# NUC400_v1 register map
File version: 1.0
Registers are 32-bit, read-write, reset 0x0 unless marked. A register's access mark holds for its fields unless they carry their own. Offsets are from the block's base; [hi:lo] are bit positions; {n}, {i} and the like mark numbered series; 'fields as' and 'values as' point back to an identical list.

## PWM0 — PWM Register Map
Base 0x40058000
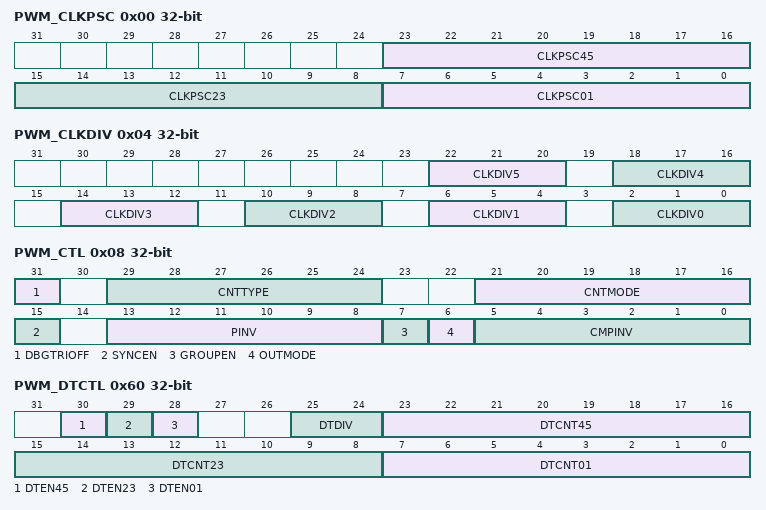
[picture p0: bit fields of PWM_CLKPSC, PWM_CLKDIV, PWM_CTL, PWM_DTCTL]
0x00 PWM_CLKPSC — PWM Clock Prescale Register
  [23:16] CLKPSC45 — PWM Counter Base-Clock Prescale For PWM Pair Of Channel 4 And Channel 5. The base-clock of PWM counter is decided by clock pre-scalar and clock divider. Each PWM pair share one PWM counter base-clock prescaler. The base-clock of PWM counter is divided by (CLKPSC45 + 1). If the value of CLKPSC45 is zero, the base-clock prescaler will stop output clock and corresponding PWM counter will also stop.
  [15:8] CLKPSC23 — PWM Counter Base-Clock Prescale For PWM Pair Of Channel 2 And Channel 3. The base-clock of PWM counter is decided by clock pre-scalar and clock divider. Each PWM pair share one PWM counter base-clock prescaler. The base-clock of PWM counter is divided by (CLKPSC23 + 1). If the value of CLKPSC23 is zero, the base-clock prescaler will stop output clock and corresponding PWM counter will also stop.
  [7:0] CLKPSC01 — PWM Counter Base-Clock Prescale For PWM Pair Of Channel 0 And Channel 1. The base-clock of PWM counter is decided by clock pre-scalar and clock divider. Each PWM pair share one PWM counter base-clock prescaler. The base-clock of PWM counter is divided by (CLKPSC01 + 1). If the value of CLKPSC01 is zero, the base-clock prescaler will stop output clock and corresponding PWM counter will also stop.
0x04 PWM_CLKDIV — PWM Clock Divide Register
  [22:20] CLKDIV5 — PWM Counter Base-Clock Divide For PWMx_CH5. The base-clock of PWM counter is decided by clock pre-scalar and clock divider. Each PWM counter has independent clock divider control register and the divided value is listed in the table below:
    0=2; 1=4; 2=8; 3=16; 4=1
  [4n+2:4n] CLKDIV{n} (n=0..4) — PWM Counter Base-Clock Divide For PWMx_CH{n} (Table is the same as CLKDIV5)
0x08 PWM_CTL — PWM Control Register
  [31] DBGTRIOFF — ICE Debug Mode Acknowledge Disable Bit (Write Protect). Note: The PWM pin will keep output no matter ICE debug mode acknowledged or not.
    0=ICE debug mode acknowledgement effects PWM output; 1=ICE debug mode acknowledgement disabled
  [29:24] CNTTYPE — PWM Counter Operation Aligned Type. Note: Each bit control corresponding PWM channel
    0=PWM counter operating as Edge-aligned type; 1=PWM counter operating as Center-aligned type
  [21:16] CNTMODE — PWM Counter Operation Mode. Note: Each bit control corresponding PWM channel. Note: If there is a transition at this bit, it will cause PWM_PERIODn and PWM_CMPDATn be cleared.
    0=PWM counter working as One-shot mode; 1=PWM counter working as Auto-reload mode
  [15] SYNCEN — Synchronous Mode Enable Bit. Note: If Group and Synchronous mode are enabled simultaneously, the Synchronous mode will be inactive.
    0=The signals timing of each PWM channel are independent; 1=Unify the signals timing of PWM_CH0 and PWM_CH1 in the same phase which is controlled by PWM0 and so as another two PWM pair
  [13:8] PINV — PWM Output Polar Inverse Enable Bit. The register controls polarity state of PWM output. Note: Each bit controls the corresponding PWM channel.
    0=PWM output polar inverse Disabled; 1=PWM output polar inverse Enabled
  [7] GROUPEN — Group Mode Enable Bit
    0=The signals timing of each PWM channel are independent; 1=Unify the signals timing of PWM_CH0, PWM_CH2 and PWM_CH4 in the same phase which is controlled by PWM_CH0 and unify the signals timing of PWM_CH1, PWM_CH3 and PWM_CH5 in the same phase which is controlled by PWM_CH1
  [6] OUTMODE — PWM Output Mode. The register controls the output mode of PWM
    0=PWM output at independent mode; 1=PWM output at complementary mode
  [5:0] CMPINV — PWM Comparator Output Inverter Enable Bit. When CMPINV is set to high, the PWM comparator output signals will be inversed, Note: Each bit control corresponding PWM channel
    0=Comparator output inverter Disabled; 1=Comparator output inverter Enabled
0x0C PWM_CNTEN — PWM Counter Enable Control Register
  [5:0] CNTEN — PWM Counter Enable Bit. Note: Each bit controls the corresponding PWM channel.
    0=PWM Counter Stop Running; 1=PWM Counter Start Running
{0x10+4i} PWM_PERIOD{i} (i=0..5) — PWM Period Register {i}
  [15:0] PERIOD — PWM Period Register. PERIOD determines the PWM period. Note1: Any write to PERIOD will take effect in next PWM cycle. Note2: When PWM operating at center-aligned type, PERIOD value should be set between 0x0000 to 0xFFFE. If PERIOD equal to 0xFFFF, the PWM will work unpredictable. Note3: When PERIOD value is set to 0, PWM output is always high.
{0x28+4i} PWM_CMPDAT{i} (i=0..5) — PWM Comparator Register {i}
  [15:0] CMP — PWM Compare Register. CMP determines the PWM duty. Note: Any write to CMP will take effect in next PWM cycle.
{0x40+4i} PWM_CNT{i} ro (i=0..5) — PWM Data Register {i}
  [15:0] CNT — PWM Data Register. User can monitor CNT to know the current value in 16-bit down counter. Note: It is recommended that read this register when PWM engine clock is source from system clock, otherwise a transition value of PWM counter may be read.
0x58 PWM_MSKEN — PWM Mask Control Register
  [5:0] MSKEN — PWM Mask Enable Bits. The PWM output signal will be masked when this bit is enabled. The corresponding PWMn channel will be output with MSKDAT data. Note: Each bit controls the corresponding PWM channel.
    0=PWM output signal is non-masked; 1=PWM output signal is masked and output with MSKDAT data
0x5C PWM_MSK — PWM Mask Data Register
  [5:0] MSKDAT — PWM Mask Data Bit: This data bit control the state of PWMn output pin, if corresponding mask function is enabled. Note: Each bit controls the corresponding PWM channel.
    0=Output logic low to PWMn; 1=Output logic high to PWMn
0x60 PWM_DTCTL — PWM Dead-zone Control Register
  [30] DTEN45 — Dead-Zone Enable Control for PWM Pair Of Channel 4 and Channel 5. Dead-zone insertion is only active when this pair of complementary PWM is enabled. If Dead-zone insertion is inactive, the outputs of pin pair are complementary without any delay.
    0=Dead-zone insertion Disabled; 1=Dead-zone insertion Enabled
  [29] DTEN23 — Dead-Zone Enable Control for PWM Pair Of Channel 2 and Channel 3. Dead-zone insertion is only active when this pair of complementary PWM is enabled. If Dead-zone insertion is inactive, the outputs of pin pair are complementary without any delay.
    values as DTEN45
  [28] DTEN01 — Dead-Zone Enable Control for PWM Pair Of Channel 0 and Channel 1. Dead-zone insertion is only active when this pair of complementary PWM is enabled. If Dead-zone insertion is inactive, the outputs of pin pair are complementary without any delay.
    values as DTEN45
  [25:24] DTDIV — Dead-Zone Generator Divider
    0=Dead-zone clock equal to PWM base clock divide 1; 1=Dead-zone clock equal to PWM base clock divide 2; 2=Dead-zone clock equal to PWM base clock divide 4; 3=Dead-zone clock equal to PWM base clock divide 8
  [23:16] DTCNT45 — Dead-Zone Interval For PWM Pair Of Channel 4 And Channel 5. These 8-bit determine the Dead-zone length. The unit time of Dead-zone length is received from corresponding PWM_CLKDIV.
  [15:8] DTCNT23 — Dead-Zone Interval For PWM Pair Of Channel 2 And Channel 3. These 8-bit determine the Dead-zone length. The unit time of Dead-zone length is received from corresponding PWM_CLKDIV.
  [7:0] DTCNT01 — Dead-Zone Interval For PWM Pair Of Channel 0 And Channel 1. These 8-bit determine the Dead-zone length. The unit time of Dead-zone length is received from corresponding PWM_CLKDIV.
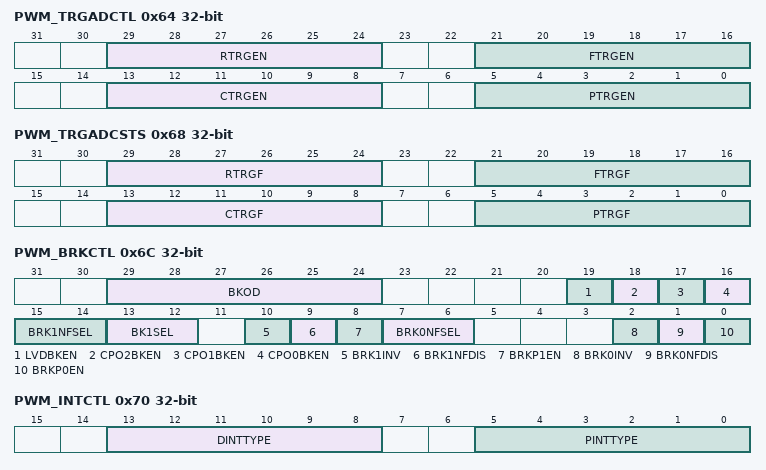
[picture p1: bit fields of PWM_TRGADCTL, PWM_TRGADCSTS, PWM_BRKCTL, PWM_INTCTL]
0x64 PWM_TRGADCTL — PWM Trigger Control Register
  [29:24] RTRGEN — PWM Rising Edge Point Trigger Enable Bits. PWM can trigger ADC to start conversion when PWM output pin rising edge is detected if this bit is set to1. Note: Each bit controls the corresponding PWM channel.
    0=PWM rising edge point trigger ADC function Disabled; 1=PWM rising edge point trigger ADC function Enabled
  [21:16] FTRGEN — PWM Falling Edge Point Trigger Enable Bits. PWM can trigger ADC to start conversion when PWM output pin falling edge is detected if this bit is set to1. Note: Each bit controls the corresponding PWM channel.
    0=PWM falling edge point trigger ADC function Disabled; 1=PWM falling edge point trigger ADC function Enabled
  [13:8] CTRGEN — PWM Center Point Trigger Enable Bits. PWM can trigger ADC to start conversion when PWM counter up count to (PERIODn+1) if this bit is set to1. Note1: This bit should keep at 0 when PWM counter operating in Edge-aligned type. Note2: Each bit controls the corresponding PWM channel.
    0=PWM center point trigger ADC function Disabled; 1=PWM center point trigger ADC function Enabled
  [5:0] PTRGEN — PWM Period Point Trigger Enable Bits. PWM can trigger ADC to start conversion when PWM counter down count to zero if this bit is set to1. Note: Each bit controls the corresponding PWM channel.
    0=PWM period point trigger ADC function Disabled; 1=PWM period point trigger ADC function Enabled
0x68 PWM_TRGADCSTS — PWM Trigger ADC Status Register
  [29:24] RTRGF — PWM Rising Edge Point Trigger Indicator. This bit is set to 1 by hardware when PWM output pin rising edge is detected if corresponding RETRGEN bit is 1. After this bit is set to 1, ADC will start conversion if ADC triggered source is selected by PWM. Note1: Write 1 to clear this bit. Note2: Each bit controls the corresponding PWM channel.
  [21:16] FTRGF — PWM Falling Edge Point Trigger Indicator. This bit is set to 1 by hardware when PWM output pin falling edge is detected if corresponding FETRGEN bit is 1. After this bit is set to 1, ADC will start conversion if ADC triggered source is selected by PWM. Note1: Write 1 to clear this bit. Note2: Each bit controls the corresponding PWM channel.
  [13:8] CTRGF — PWM Center Point Trigger Flag. This bit is set to 1 by hardware when PWM counter up counts to (PERIODn+1) if the corresponding CTRGEN bit is 1. After this bit is set to 1, ADC will start conversion if ADC triggered source is selected by PWM. Note1: Write 1 to clear this bit. Note2: Each bit controls the corresponding PWM channel.
  [5:0] PTRGF — PWM Period Point Trigger Flag. This bit is set to 1 by hardware when PWM counter down count to zero if corresponding PTRGEN bit is 1. After this bit is set to 1, ADC will start conversion if ADC triggered source is selected by PWM. Note1: Write 1 to clear this bit. Note2: Each bit controls the corresponding PWM channel.
0x6C PWM_BRKCTL — PWM Brake Control Register
  [29:24] BKOD — PWM Brake Output Data Register. Note: Each bit controls the corresponding PWM channel.
    0=PWM output low when fault brake conditions asserted; 1=PWM output high when fault brake conditions asserted
  [19] LVDBKEN — Low-Level Detection Trigger PWM Brake Function 1 Enable Bit
    0=Brake Function 1 triggered by Low-level detection Disabled; 1=Brake Function 1 triggered by Low-level detection Enabled
  [18] CPO2BKEN — CPO2 Digital Output As Brake 0 Source Enable Bit
    0=CPO2 as one brake source in Brake 0 Disabled; 1=CPO2 as one brake source in Brake 0 Enabled
  [17] CPO1BKEN — CPO1 Digital Output As Brake 0 Source Enable Bit
    0=CPO1 as one brake source in Brake 0 Disabled; 1=CPO1 as one brake source in Brake 0 Enabled
  [16] CPO0BKEN — CPO0 Digital Output As Brake0 Source Enable Bit
    0=CPO0 as one brake source in Brake 0 Disabled; 1=CPO0 as one brake source in Brake 0 Enabled
  [15:14] BRK1NFSEL — Brake 1 (BKPx1 Pin) Edge Detector Filter Clock Selection
    0=Filter clock = HCLK; 1=Filter clock = HCLK/2; 2=Filter clock = HCLK/4; 3=Filter clock = HCLK/16
  [13:12] BK1SEL — Brake Function 1 Source Selection
    0=From external pin BKP1; 1=From analog comparator 0 output (CPO0); 2=From analog comparator 1 output (CPO1)
  [10] BRK1INV — Inverse BKP1 State
    0=The state of pin BKPx1 is passed to the negative edge detector; 1=The inversed state of pin BKPx1 is passed to the negative edge detector
  [9] BRK1NFDIS — PWM Brake 1 Noise Filter Disable Bit
    0=Noise filter of PWM Brake 1 Enabled; 1=Noise filter of PWM Brake 1 Disabled
  [8] BRKP1EN — Brake1 Function Enable Bit
    0=Brake1 function Disabled; 1=Brake1 function Enabled
  [7:6] BRK0NFSEL — Brake 0 (BKPx0 Pin) Edge Detector Filter Clock Selection
    values as BRK1NFSEL
  [2] BRK0INV — Inverse BKP0 State
    0=The state of pin BKPx0 is passed to the negative edge detector; 1=The inversed state of pin BKPx0 is passed to the negative edge detector
  [1] BRK0NFDIS — PWM Brake 0 Noise Filter Disable Bit
    0=Noise filter of PWM Brake 0 Enabled; 1=Noise filter of PWM Brake 0 Disabled
  [0] BRKP0EN — Brake0 Function Enable Bit
    0=Brake0 detect function Disabled; 1=Brake0 detect function Enabled
0x70 PWM_INTCTL — PWM Interrupt Control Register
  [13:8] DINTTYPE — PWM Duty Interrupt Type Selection. Note1: This bit should keep at 0 when PWM counter operating in Edge-aligned type. Note2: Each bit controls the corresponding PWM channel.
    0=DIF[n] will be set if PWM counter matches PWM_CMPDATn register during down counting; 1=DIF[n] will be set if PWM counter matches PWM_CMPDATn register during up counting
  [5:0] PINTTYPE — PWM Period Interrupt Type Selection. Note1: This bit should keep at 0 when PWM counter operating in Edge-aligned type. Note2: Each bit controls the corresponding PWM channel.
    0=PIF[n] will be set if PWM counter underflow; 1=PIF[n] will be set if PWM counter matches PWM_PERIODn register
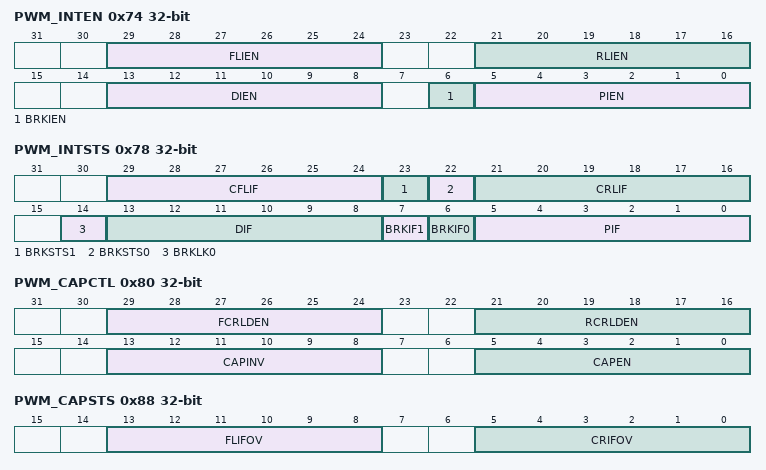
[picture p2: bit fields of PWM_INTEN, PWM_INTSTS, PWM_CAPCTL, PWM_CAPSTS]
0x74 PWM_INTEN — PWM Interrupt Enable Control Register
  [29:24] FLIEN — Falling Latch Interrupt Enable Bit. Note: Each bit controls the corresponding PWM channel.
    0=Falling latch interrupt Disabled; 1=Falling latch interrupt Enabled
  [21:16] RLIEN — Rising Latch Interrupt Enable Bits. Note: Each bit controls the corresponding PWM channel.
    0=Rising latch interrupt Disabled; 1=Rising latch interrupt Enabled
  [13:8] DIEN — PWM Duty Interrupt Enable Bits. Note: Each bit controls the corresponding PWM channel.
    0=Duty interrupt Disabled; 1=Duty interrupt Enabled
  [6] BRKIEN — Brake0 and Brak1 Interrupt Enable Bit
    0=Disabling flags BFK0 and BFK1 to trigger PWM interrupt; 1=Enabling flags BRKIF0 and BRKIF1 can trigger PWM interrupt
  [5:0] PIEN — PWM Period Interrupt Enable Bits. Note: Each bit controls the corresponding PWM channel.
    0=Period interrupt Disabled; 1=Period interrupt Enabled
0x78 PWM_INTSTS — PWM Interrupt Flag Register
  [29:24] CFLIF — Capture Falling Latch Interrupt Flag. Note: This bit must be cleared by writing 1 to it.
    0=No capture falling latch condition happened; 1=Capture falling latch condition happened, this flag will be set to high
  [23] BRKSTS1 ro — Brake 1 Status (Read Only)
    0=PWM had been out of Brake 1 state; 1=PWM is in Brake 1 state
  [22] BRKSTS0 ro — Brake 0 Status (Read Only)
    0=PWM had been out of Brake 0 state; 1=PWM is in Brake 0 state
  [21:16] CRLIF — Capture Rising Latch Interrupt Flag. Note: This bit must be cleared by writing 1 to it.
    0=No capture rising latch condition happened; 1=Capture rising latch condition happened, this flag will be set to high
  [14] BRKLK0 — PWM Brake0 Locked. Note: This bit must be cleared by writing 1 to it.
    0=Brake 0 state is released; 1=When PWM Brake detects a falling signal at BKP0, this flag will be set to high to indicate the Brake0 state is locked
  [13:8] DIF — PWM Duty Interrupt Flag. Flag is set by hardware when channel 0 PWM counter down count and reaches CMP0. Software can clear this bit by writing 1 to it. Note: If CMP is equal to PERIOD, this flag is not working in edge-aligned type selection.
  [7] BRKIF1 — PWM Brake1 Flag. Note: This bit must be cleared by writing 1 to it.
    0=PWM Brake 1 is able to poll falling signal at BKP1 and has not recognized any one; 1=When PWM Brake 1 detects a falling signal at pin BKP1, this flag will be set to high
  [6] BRKIF0 — PWM Brake0 Flag. Note: This bit must be cleared by writing 1 to it.
    0=PWM Brake 0 is able to poll falling signal at BKP0 and has not recognized any one; 1=When PWM Brake 0 detects a falling signal at BKP0, this flag will be set to high
  [5:0] PIF — PWM Period Interrupt Flag. This bit is set by hardware when PWM counter reaches the requirement condition of interrupt (depending on PINTTYPE (PWM_INTCTL[n]) ). Software can write 1 to clear this bit to 0.
0x7C PWM_POEN — PWM Output Enable Control Register
  [5:0] POEN — PWM Pin Output Enable Bit. Note: Each bit controls the corresponding PWM channel.
    0=PWM pin at tri-state; 1=PWM pin in output mode
0x80 PWM_CAPCTL — PWM Capture Control Register
  [29:24] FCRLDEN — Falling Latch Reload Enable Bits
    0=Falling latch reload counter Disabled; 1=Falling latch reload counter Enabled
  [21:16] RCRLDEN — Rising Latch Reload Enable Bits
    0=Rising latch reload counter Enabled; 1=Rising latch reload counter Enabled
  [13:8] CAPINV — Capture Inverter Enable Bits. Note: Each bit controls the corresponding PWM channel.
    0=Capture source inverter Disabled; 1=Capture source inverter Enabled. Reverse the input signal from GPIO
  [5:0] CAPEN — Capture Function Enable Bits. Note: Each bit controls the corresponding PWM channel.
    0=Capture function Disabled. RCAPDAT and FCAPDAT will not be updated; 1=Capture function Enabled. Capture latched the PWM counter value and saved to RCAPDAT (Rising latch) and FCAPDAT (Falling latch)
0x84 PWM_CAPINEN — PWM Capture Input Enable Control Register
  [5:0] CAPINEN — Capture Input Enable Bits. Note: Each bit controls the corresponding PWM channel.
    0=PWM Channel capture input path Disabled. The input of PWM channel capture function is always regarded as 0; 1=PWM Channel capture input path Enabled. The input of PWM channel capture function comes from correlative multifunction pin
0x88 PWM_CAPSTS ro — PWM Capture Status Register
  [13:8] FLIFOV — Falling Latch Interrupt Flag Overrun Status. This flag indicates if falling latch happened when the corresponding CFLIF is 1. Note: This bit will be cleared automatically when user clear corresponding CFLIF.
  [5:0] CRIFOV — Rising Latch Interrupt Flag Overrun Status. This flag indicates if rising latch happened when the corresponding CRLIF is 1. Note: This bit will be cleared automatically when user clear corresponding CRLIF.
{0x90+8i} PWM_RCAPDAT{i} ro (i=0..5) — PWM Capture Rising Latch Register {i}
  [15:0] RCAPDAT — Capture Rising Latch Register. Latch the PWM counter when Channel 0/1/2/3/4/5 has rising transition.
{0x94+8i} PWM_FCAPDAT{i} ro (i=0..5) — PWM Capture Falling Latch Register {i}
  [15:0] FCAPDAT — Capture Falling Latch Register. Latch the PWM counter when Channel 0/1/2/3/4/5 has Falling transition.
0xE0 PWM_SBS0 ro — PWM0 Synchronous Busy Status Register
  [0] SYNCBUSY — PWM Synchronous Busy. When software writes PWM_PERIOD0/PWM_CMPDAT0/PWM_CLKPSC or switch PWM0 counter operation mode CNTMOD (PWM_CTL[16]), PWM will have a busy time to update these values completely because PWM clock may be different from system clock domain. Software needs to check this busy status before writes PWM_PERIOD0/PWM_CMPDAT0/ PWM_CLKPSC or switch PWM0 counter operation mode to make sure previous setting has been update completely. This bit will be set when software writes PWM_PERIOD0/PWM_CMPDAT0/PWM_CLKPSC or switch PWM0 operation mode CNTMOD (PWM_CTL[16]) and will be cleared by hardware automatically when PWM update these value completely.
{0xE0+4i} PWM_SBS{i} ro (i=1..5) — PWM{i} Synchronous Busy Status Register
  [0] SYNCBUSY — PWM Synchronous Busy. When software writes PWM_PERIOD{i}/PWM_CMPDAT{i}/PWM_CLKPSC or switch PWM{i} counter operation mode CNTMOD (PWM_CTL [{i+16}]), PWM will have a busy time to update these values completely because PWM clock may be different from system clock domain. Software needs to check this busy status before writes PWM_PERIOD{i}/PWM_CMPDAT{i}/ PWM_CLKPSC or switch PWM{i} counter operation mode to make sure previous setting has been update completely. This bit will be set when software writes PWM_PERIOD{i}/PWM_CMPDAT{i}/PWM_CLKPSC or switch PWM{i} operation mode CNTMOD (PWM_CTL [{i+16}]) and will be cleared by hardware automatically when PWM update these value completely.

## PWM1 — PWM Register Map
Base 0x40059000
Registers as PWM0; these are added or differ:
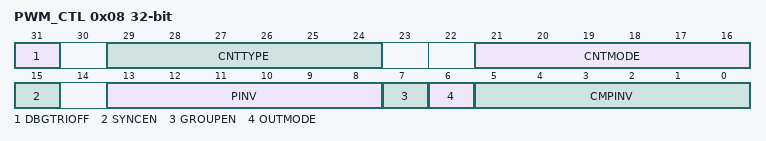
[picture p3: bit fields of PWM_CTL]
0x08 PWM_CTL — PWM Control Register
  fields as PWM0.PWM_CTL
0xE0 PWM_SBS0 ro — PWM0 Synchronous Busy Status Register
  fields as PWM0.PWM_SBS0
0xE4 PWM_SBS1 ro — PWM1 Synchronous Busy Status Register
  [0] SYNCBUSY — PWM Synchronous Busy. When software writes PWM_PERIOD1/PWM_CMPDAT1/PWM_CLKPSC or switch PWM1 counter operation mode CNTMOD (PWM_CTL [17]), PWM will have a busy time to update these values completely because PWM clock may be different from system clock domain. Software needs to check this busy status before writes PWM_PERIOD1/PWM_CMPDAT1/ PWM_CLKPSC or switch PWM1 counter operation mode to make sure previous setting has been update completely. This bit will be set when software writes PWM_PERIOD1/PWM_CMPDAT1/PWM_CLKPSC or switch PWM1 operation mode CNTMOD (PWM_CTL [17]) and will be cleared by hardware automatically when PWM update these value completely.
